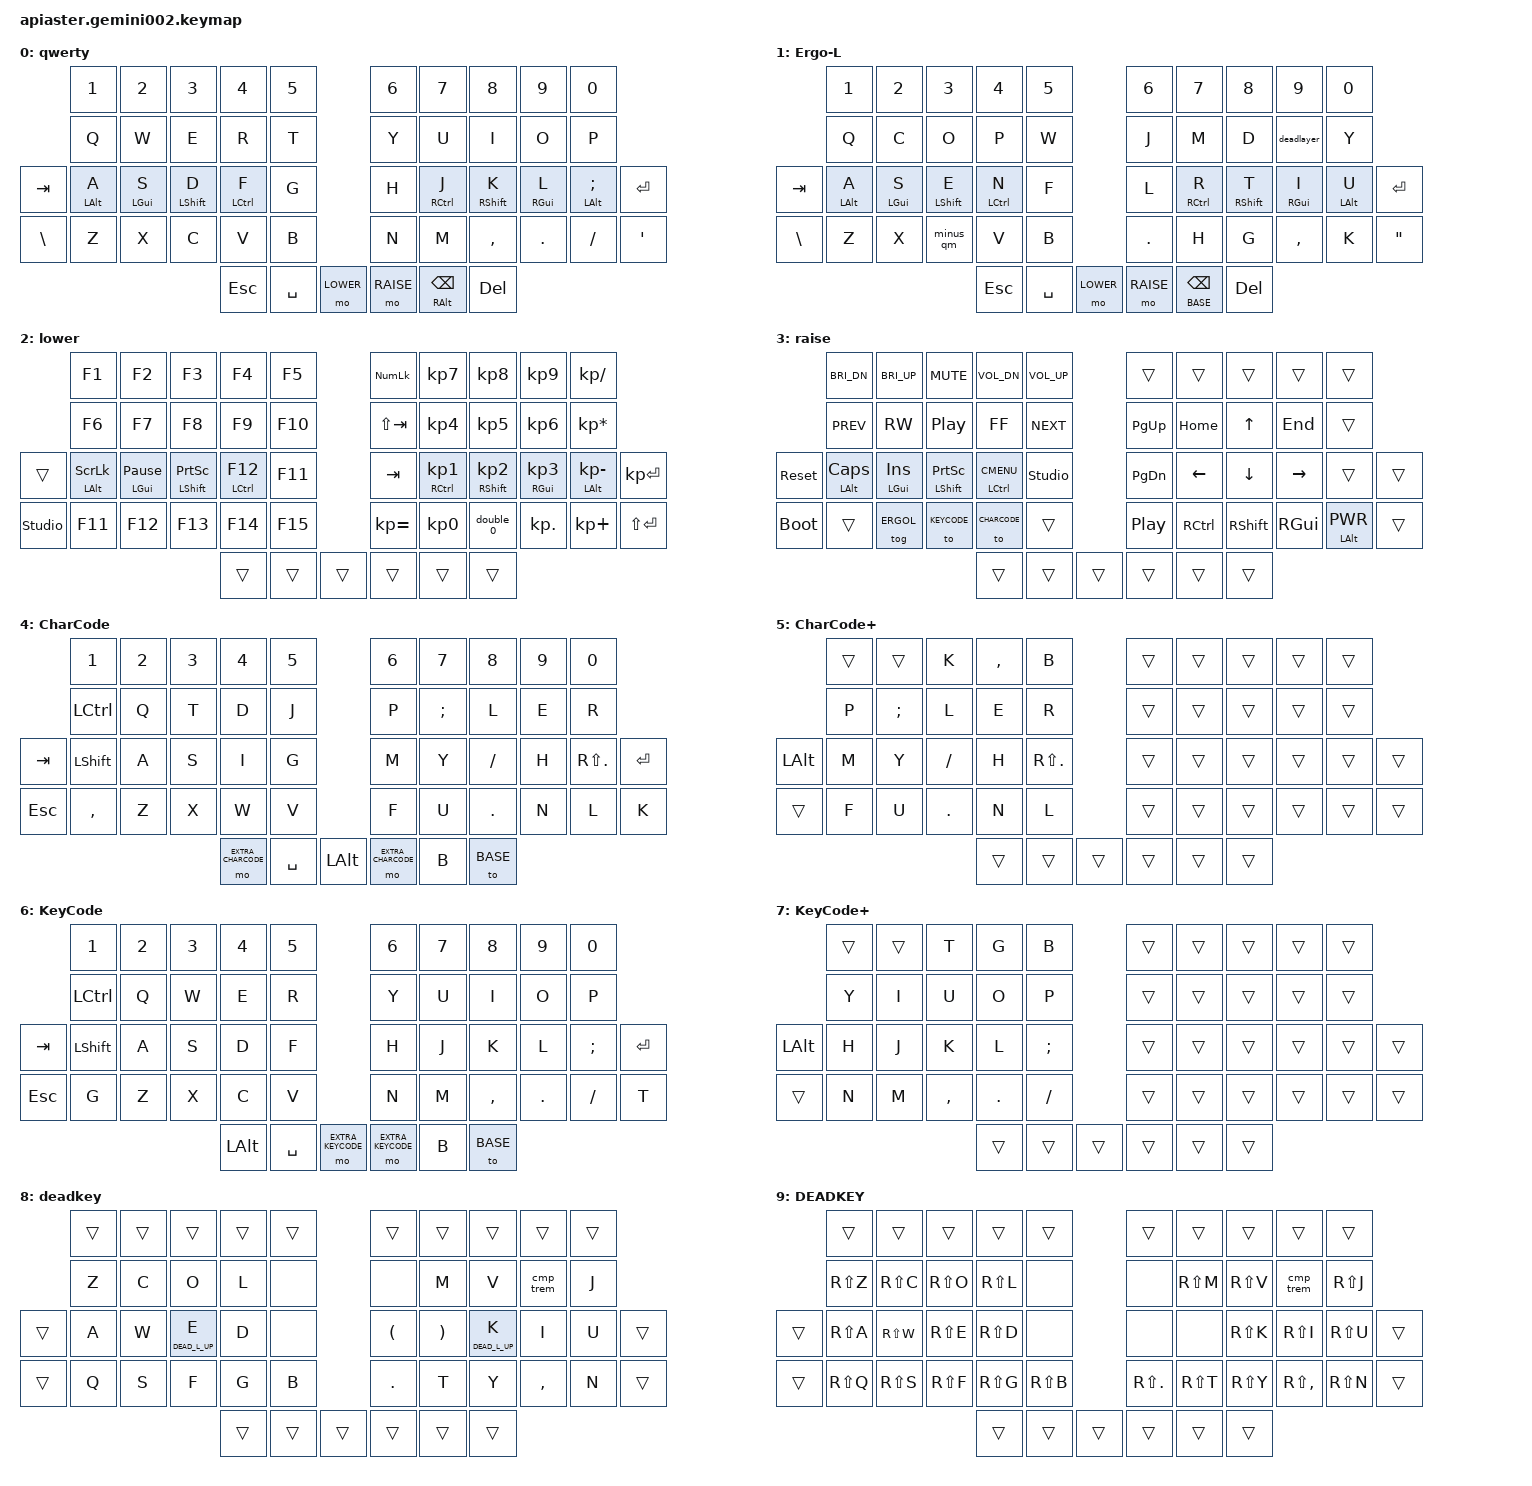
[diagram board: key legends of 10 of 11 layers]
#include <behaviors.dtsi>
#include <dt-bindings/zmk/keys.h>
#include <dt-bindings/zmk/bt.h>

#define BASE 0
#define ERGOL 1
#define LOWER 2
#define RAISE 3
#define CHARCODE 4
#define EXTRA_CHARCODE 5
#define KEYCODE 6
#define EXTRA_KEYCODE 7
#define DEAD_L 8
#define DEAD_UP_L 9
#define SYM_LAYER 10
#define ALTGR_LAYER 11 // Nouvelle définition de la couche AltGr

#define KEYS_L 0 1 2 3 4 10 11 12 13 14 20 21 22 23 24 25 32 33 34 35 36 37
#define KEYS_R 5 6 7 8 9 15 16 17 18 19 26 27 28 29 30 31 38 39 40 41 42 43
#define THUMBS_L 44 45 46
#define THUMBS_R 47 48 49

#define COMPOSE_KEY RALT

/ {    
    macros {
        double_0: double_0 {
            compatible = "zmk,behavior-macro";
            #binding-cells = <0>;
            bindings
                = <&macro_tap &kp KP_NUMBER_0>
                , <&macro_tap &kp KP_NUMBER_0>;
        };

        // Macro deadlayer : active la couche DEAD_L (lettres accentuées minuscules)
        deadlayer: deadlayer {
            compatible = "zmk,behavior-macro";
            #binding-cells = <0>;
            bindings
                // SEMI transitionne Lafayette sur sa couche d’accents et DEAD_L réarrange Lafayette-deadkey en Ergo-L-deadkey
                = <&macro_tap &kp SEMI>
                , <&sl DEAD_L>; 
        };

        // Ergo-L Macros (conservées si elles sont toujours utilisées ailleurs ou pour référence)
        cmp_sq: compose_accents_single_quote {
            compatible = "zmk,behavior-macro-one-param";
            #binding-cells = <1>;
            bindings
                = <&macro_tap &kp COMPOSE_KEY>
                , <&macro_tap &kp SINGLE_QUOTE>
                , <&macro_param_1to1>
                , <&macro_tap &kp MACRO_PLACEHOLDER>;
        };

        cmp_gq: compose_accents_grave_quote {
            compatible = "zmk,behavior-macro-one-param";
            #binding-cells = <1>;
            bindings
                = <&macro_tap &kp COMPOSE_KEY>
                , <&macro_tap &kp GRAVE>
                , <&macro_param_1to1>
                , <&macro_tap &kp MACRO_PLACEHOLDER>;
        };

        cmp_car: compose_accents_caret {
            compatible = "zmk,behavior-macro-one-param";
            #binding-cells = <1>;
            bindings
                = <&macro_tap &kp COMPOSE_KEY>
                , <&macro_tap &kp CARET>
                , <&macro_param_1to1>
                , <&macro_tap &kp MACRO_PLACEHOLDER>;
        };

        cedille: compose_cedille {
            compatible = "zmk,behavior-macro";
            #binding-cells = <0>;
            bindings
                = <&macro_tap &kp COMPOSE_KEY>
                , <&macro_tap &kp COMMA>
                , <&macro_tap &kp C>;
        };

        cmp_oe: compose_oe_char {
            compatible = "zmk,behavior-macro";
            #binding-cells = <0>;
            bindings
                = <&macro_tap &kp COMPOSE_KEY>
                , <&macro_tap &kp O>
                , <&macro_tap &kp E>;
        };

        cmp_micro: compose_micro_char {
            compatible = "zmk,behavior-macro";
            #binding-cells = <0>;
            bindings
                = <&macro_tap &kp COMPOSE_KEY>
                , <&macro_tap &kp M>
                , <&macro_tap &kp U>;
        };
        
        cmp_trem: compose_trema {
            compatible = "zmk,behavior-macro";
            #binding-cells = <0>;
            bindings
                = <&macro_tap &kp SEMI>
                , <&macro_tap &kp SEMI>;
        };
    };

    behaviors {
        hl: home_row_hold_tap_left {
            compatible = "zmk,behavior-hold-tap";
            #binding-cells = <2>;
            flavor = "balanced";
            tapping-term-ms = <280>;
            quick-tap-ms = <175>;
            require-prior-idle-ms = <150>;
            bindings = <&kp>, <&kp>;
            hold-trigger-key-positions = <KEYS_R THUMBS_R>;
            hold-trigger-on-release;
        };

        hr: home_row_hold_tap_right {
            compatible = "zmk,behavior-hold-tap";
            #binding-cells = <2>;
            flavor = "balanced";
            tapping-term-ms = <280>;
            quick-tap-ms = <175>;
            require-prior-idle-ms = <150>;
            bindings = <&kp>, <&kp>;
            hold-trigger-key-positions = <KEYS_L THUMBS_L>;
            hold-trigger-on-release;
        };

        // Nouveau comportement hg pour la couche BASE de ZMK
        // Quand FCITX est en mode Ergo-L, les touches AltGr sont gérées par FCITX.
        // Ce hold-tap passe juste les keycodes RALT et BSPC.
        hg_base: home_row_hold_tap_altgr_base {
             compatible = "zmk,behavior-hold-tap";
            #binding-cells = <2>;
            tapping-term-ms = <225>;
            flavor = "hold-preferred";
            // Accepte deux keypresses en arguments (ex: RALT et BSPC)
            bindings = <&kp>, <&kp>; 
        };

        // Nouveau comportement hg pour la couche ERGOL de ZMK
        // Quand FCITX est en mode QWERTY-Lafayette, nous utilisons une couche momentanée
        // pour accéder aux caractères AltGr directement via ZMK.
        hg_ergol: home_row_hold_tap_altgr_ergol {
             compatible = "zmk,behavior-hold-tap";
            #binding-cells = <2>;
            tapping-term-ms = <225>;
            flavor = "hold-preferred";
            // Accepte un behavior de couche momentanée (&mo) et un keypress (&kp)
            bindings = <&mo>, <&kp>; 
        };

        td_rst: reset_tap_dance {
            compatible = "zmk,behavior-tap-dance";
            #binding-cells = <0>;
            tapping-term-ms = <200>;
            bindings = <&sys_reset>, <&bootloader>;
        };

        // Ergo-L Behaviors
        dot_col: dot_colon {
            compatible = "zmk,behavior-mod-morph";
            #binding-cells = <0>;
            bindings = <&kp DOT>, <&kp COLON>;
            mods = <(MOD_LSFT|MOD_RSFT)>;
        };

        com_scol: comma_semicolon {
            compatible = "zmk,behavior-mod-morph";
            #binding-cells = <0>;
            bindings = <&kp COMMA>, <&kp SEMICOLON>;
            mods = <(MOD_LSFT|MOD_RSFT)>;
        };

        minus_qm: minus_question {
            compatible = "zmk,behavior-mod-morph";
            #binding-cells = <0>;
            bindings = <&kp MINUS>, <&kp QUESTION>;
            mods = <(MOD_LSFT|MOD_RSFT)>;
        };

        dead_key: dead_key {
            compatible = "zmk,behavior-mod-morph";
            #binding-cells = <0>;
            bindings = <&sl DEAD_L>, <&kp EXCL>;
            mods = <(MOD_LSFT|MOD_RSFT)>;
        };

        // Nouveau behavior hold-tap pour changer vers DEAD_L_UP
        htdl: hold_tap_deadlup {
            compatible = "zmk,behavior-hold-tap";
            #binding-cells = <2>;
            tapping-term-ms = <225>;
            flavor = "hold-preferred";
            // Le premier argument sera le behavior de la couche à activer sur maintien (&mo)
            // Le second argument sera le behavior de la touche à taper sur appui simple (&kp)
            bindings = <&mo>, <&kp>; 
        };
    };

    keymap {
        compatible = "zmk,keymap";

        qwerty_layer {
            display-name = "qwerty";
            bindings = <
          &kp N1     &kp N2     &kp N3      &kp N4      &kp N5                      &kp N6    &kp N7      &kp N8      &kp N9     &kp N0
          &kp Q      &kp W      &kp E       &kp R       &kp T                       &kp Y     &kp U       &kp I       &kp O      &kp P
&kp TAB   &hl LALT A &hl LGUI S &hl LSHFT D &hl LCTRL F &kp G                       &kp H     &hr RCTRL J &hr RSHFT K &hr RGUI L &hr LALT SEMI &kp ENTER
&kp BSLH &kp Z      &kp X      &kp C       &kp V       &kp B                       &kp N     &kp M       &kp COMMA   &kp DOT    &kp FSLH      &kp SQT
                                            &kp ESC &kp SPACE &mo LOWER &mo RAISE &hg_base RALT BSPC &kp DEL
            >;
        };

        ergo_base_layer {
            display-name = "Ergo-L";
            bindings = <
          &kp N1      &kp N2     &kp N3     &kp N4       &kp N5                      &kp N6   &kp N7      &kp N8      &kp N9        &kp N0
          &kp Q       &kp C      &kp O      &kp P        &kp W                       &kp J    &kp M       &kp D       &deadlayer    &kp Y
 &kp TAB  &hl LALT A &hl LGUI S &hl LSHFT E &hl LCTRL N  &kp F                       &kp L    &hr RCTRL R &hr RSHFT T &hr RGUI I   &hr LALT U &kp ENTER
 &kp BSLH &kp Z       &kp X      &minus_qm  &kp V        &kp B                       &kp DOT &kp H       &kp G       &kp COMMA    &kp K      &kp DOUBLE_QUOTES
                                            &kp ESC &kp SPACE &mo LOWER &mo RAISE &hg_ergol BASE BSPC &kp DEL
            >;
        };

        lower_layer {
            display-name = "lower";
            bindings = <
           &kp F1              &kp F2               &kp F3          &kp F4        &kp F5  &kp KP_NUM  &kp KP_NUMBER_7       &kp KP_NUMBER_8       &kp KP_NUMBER_9 &kp KP_DIVIDE
           &kp F6              &kp F7               &kp F8          &kp F9        &kp F10 &kp LS(TAB) &kp KP_NUMBER_4       &kp KP_NUMBER_5       &kp KP_NUMBER_6 &kp KP_MULTIPLY
&trans &hl LALT SCROLLLOCK &hl LGUI PAUSE_BREAK &hl LSHFT PSCRN &hl LCTRL F12 &kp F11 &kp TAB &hr RCTRL KP_NUMBER_1 &hr RSHFT KP_NUMBER_2 &hr RGUI KP_NUMBER_3 &hr LALT KP_SUBTRACT &kp KP_ENTER
&studio_unlock &kp F11            &kp F12              &kp F13         &kp F14       &kp F15 &kp KP_EQUAL &kp KP_NUMBER_0 &double_0 &kp KP_DOT &kp KP_PLUS &kp LS(ENTER)
                                                   &trans &trans &trans &trans &trans &trans
            >;
        };

        raise_layer {
            display-name = "raise";
            bindings = <
           &kp C_BRI_DN  &kp C_BRI_UP &kp C_MUTE      &kp C_VOL_DN      &kp C_VOL_UP        &trans    &trans    &trans    &trans    &trans
           &kp C_PREV    &kp C_RW     &kp C_PP        &kp C_FF          &kp C_NEXT          &kp PG_UP &kp HOME  &kp UP    &kp END   &trans
&sys_reset &hl LALT CLCK &hl LGUI INS &hl LSHFT PSCRN &hl LCTRL K_CMENU &studio_unlock      &kp PG_DN &kp LEFT  &kp DOWN  &kp RIGHT &trans         &trans
&bootloader &trans       &tog ERGOL   &to KEYCODE     &to CHARCODE      &trans              &kp C_PP  &kp RCTRL &kp RSHFT &kp RGUI  &hr LALT C_PWR &trans
                                               &trans &trans &trans &trans &trans &trans
            >;
        };
      
        charcode_layer {
            display-name = "CharCode";
            bindings = <
          &kp N1     &kp N2   &kp N3   &kp N4   &kp N5                            &kp N6 &kp N7    &kp N8    &kp N9 &kp N0
          &kp LCTRL  &kp Q    &kp T    &kp D    &kp J                             &kp P  &kp SEMI  &kp L     &kp E  &kp R 
&kp TAB   &kp LSHFT  &kp A    &kp S    &kp I    &kp G                             &kp M  &kp Y     &kp FSLH  &kp H  &kp RS(DOT) &kp ENTER 
&kp ESC   &kp COMMA  &kp Z    &kp X    &kp W    &kp V                             &kp F  &kp U     &kp DOT   &kp N  &kp L       &kp K 
                                       &mo EXTRA_CHARCODE &kp SPACE &kp LALT &mo EXTRA_CHARCODE &kp B &to BASE
            >;
        };

        extra_charcode_layer {
            display-name = "CharCode+";
            bindings = <
          &trans   &trans   &kp K    &kp COMMA &kp B                              &trans &trans &trans &trans &trans  
          &kp P    &kp SEMI &kp L    &kp E     &kp R                              &trans &trans &trans &trans &trans  
&kp LALT  &kp M    &kp Y    &kp FSLH &kp H     &kp RS(DOT)                        &trans &trans &trans &trans &trans &trans  
&trans    &kp F    &kp U    &kp DOT  &kp N     &kp L                              &trans &trans &trans &trans &trans &trans  
                                       &trans   &trans  &trans  &trans &trans    &trans
            >;
        };


        keycode_layer {
            display-name = "KeyCode";
            bindings = <
          &kp N1     &kp N2   &kp N3   &kp N4   &kp N5                            &kp N6 &kp N7 &kp N8 &kp N9 &kp N0
          &kp LCTRL  &kp Q    &kp W    &kp E    &kp R                             &kp Y &kp U &kp I &kp O &kp P
&kp TAB   &kp LSHFT  &kp A    &kp S    &kp D    &kp F                             &kp H &kp J &kp K &kp L &kp SEMI &kp ENTER
&kp ESC   &kp G  &kp Z    &kp X    &kp C    &kp V                             &kp N &kp M &kp COMMA &kp DOT &kp FSLH &kp T
                                       &kp LALT &kp SPACE &mo EXTRA_KEYCODE &mo EXTRA_KEYCODE &kp B &to BASE
            >;
        };

        extra_keycode_layer {
            display-name = "KeyCode+";
            bindings = <
          &trans   &trans &kp T     &kp G   &kp B                  &trans    &trans  &trans  &trans  &trans  
          &kp Y    &kp I  &kp U     &kp O   &kp P                  &trans    &trans  &trans  &trans  &trans  
&kp LALT  &kp H    &kp J  &kp K     &kp L   &kp SEMI                  &trans    &trans  &trans  &trans  &trans   &trans  
&trans    &kp N    &kp M  &kp COMMA &kp DOT &kp FSLH                  &trans    &trans  &trans  &trans  &trans   &trans  
                                       &trans   &trans  &trans  &trans &trans    &trans
            >;
        };

        // Ergo-L Layers
        dead_key_layer {
            display-name = "deadkey";
            bindings = <
          &trans &trans &trans &trans &trans           &trans &trans &trans &trans &trans
          &kp Z &kp C &kp O &kp L &none                      &none &kp M &kp V &cmp_trem &kp J
&trans &kp A &kp W &htdl DEAD_L_UP E &kp D &none     &kp LPAR &kp RPAR &htdl DEAD_L_UP K &kp I &kp U &trans
&trans &kp Q &kp S &kp F &kp G &kp B                   &kp DOT &kp T &kp Y &kp COMMA &kp N &trans
                                       &trans   &trans  &trans  &trans &trans &trans
            >;
        };

        upper_dead_key_layer {
            display-name = "DEADKEY";
            bindings = <
       &trans &trans &trans &trans &trans                             &trans &trans &trans &trans &trans
       &kp RS(Z) &kp RS(C) &kp RS(O) &kp RS(L) &none                  &none       &kp RS(M) &kp RS(V) &cmp_trem     &kp RS(J)
&trans &kp RS(A) &kp RS(W) &kp RS(E) &kp RS(D) &none                  &none       &none     &kp RS(K) &kp RS(I)     &kp RS(U) &trans
&trans &kp RS(Q) &kp RS(S) &kp RS(F) &kp RS(G) &kp RS(B)              &kp RS(DOT) &kp RS(T) &kp RS(Y) &kp RS(COMMA) &kp RS(N) &trans
                                       &trans   &trans  &trans  &trans &trans &trans
            >;
        };

        sym_layer {
            display-name = "Sym";
            bindings = <
          &trans &trans &trans &trans &trans            &trans &trans &trans &trans &trans
          &kp GRAVE       &kp AT_SIGN    &kp HASH       &kp DOLLAR      &kp PERCENT      &kp CARET     &kp AMPERSAND   &kp ASTERISK    &kp PIPE        &kp DOUBLE_QUOTES
&trans    &hl LALT LBRC  &hl LGUI LPAR  &hl LSHFT RPAR  &hl LCTRL RBRC  &kp EQUAL        &kp BACKSLASH &hr LCTRL PLUS  &hr LSHFT MINUS  &hr LGUI SLASH  &hr LALT SINGLE_QUOTE
&trans     &trans         &kp LBKT       &kp RBKT       &kp TILDE       &trans           &trans        &kp TILDE       &kp LESS_THAN   &kp GREATER_THAN &trans
                                       &trans   &trans  &trans  &trans &trans    &trans
            >;
        };
    };
};
